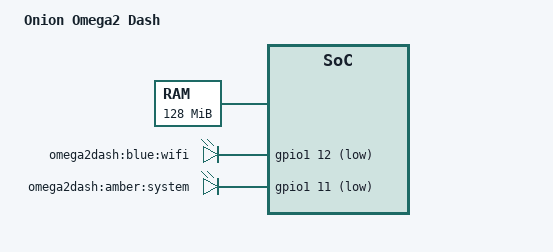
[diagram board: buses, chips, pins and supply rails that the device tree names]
/dts-v1/;

#include "OMEGA2.dtsi"

/ {
	model = "Onion Omega2 Dash";

	memory@0 {
		device_type = "memory";
		reg = <0x0 0x8000000>;
	};

	new-leds {
		compatible = "gpio-leds";

		wifi {
        	        label = "omega2dash:blue:wifi";
                	gpios = <&gpio1 12 GPIO_ACTIVE_LOW>;
        	};
	};
};

&firmware {
	reg = <0x50000 0x1f30000>;
};

&flash {
	user: partition@1f80000 {
		label = "user";
		reg = <0x1f80000 0x80000>;
	};
};

&system_led {
	label = "omega2dash:amber:system";
	gpios = <&gpio1 11 GPIO_ACTIVE_LOW>;
};
